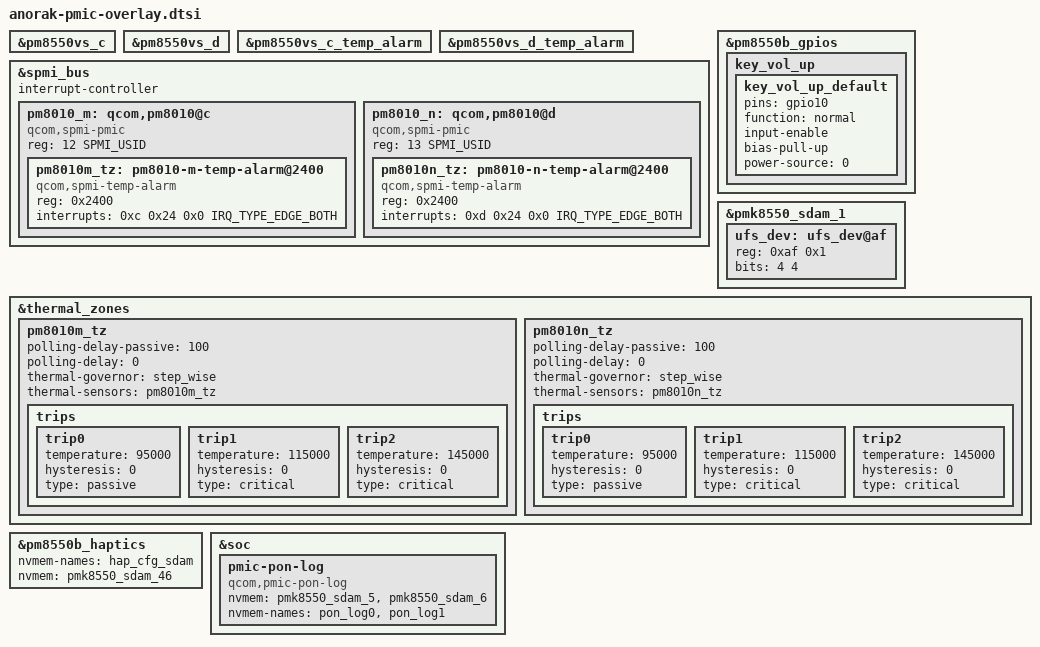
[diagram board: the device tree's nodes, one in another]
#include <dt-bindings/gpio/gpio.h>
#include <dt-bindings/pinctrl/qcom,pmic-gpio.h>

#include "pmxr2230.dtsi"
#include "pm8550b.dtsi"
#include "pm8550ve.dtsi"
#include "pm8550vs.dtsi"
#include "pmk8550.dtsi"

&pm8550vs_c {
	status = "ok";
};

&pm8550vs_d {
	status = "ok";
};

&pm8550vs_c_temp_alarm {
	status = "ok";
};

&pm8550vs_d_temp_alarm {
	status = "ok";
};

&spmi_bus {
	#address-cells = <2>;
	#size-cells = <0>;
	interrupt-controller;
	#interrupt-cells = <4>;

	pm8010_m: qcom,pm8010@c {
		compatible = "qcom,spmi-pmic";
		reg = <12 SPMI_USID>;
		#address-cells = <1>;
		#size-cells = <0>;

		pm8010m_tz: pm8010-m-temp-alarm@2400 {
			compatible = "qcom,spmi-temp-alarm";
			reg = <0x2400>;
			interrupts = <0xc 0x24 0x0 IRQ_TYPE_EDGE_BOTH>;
			#thermal-sensor-cells = <0>;
		};
	};

	pm8010_n: qcom,pm8010@d {
		compatible = "qcom,spmi-pmic";
		reg = <13 SPMI_USID>;
		#address-cells = <1>;
		#size-cells = <0>;

		pm8010n_tz: pm8010-n-temp-alarm@2400 {
			compatible = "qcom,spmi-temp-alarm";
			reg = <0x2400>;
			interrupts = <0xd 0x24 0x0 IRQ_TYPE_EDGE_BOTH>;
			#thermal-sensor-cells = <0>;
		};
	};
};

&pm8550b_gpios {
	key_vol_up {
		key_vol_up_default: key_vol_up_default {
			pins = "gpio10";
			function = "normal";
			input-enable;
			bias-pull-up;
			power-source = <0>;
		};
	};
};

&pmk8550_sdam_1 {
	ufs_dev: ufs_dev@af {
		reg = <0xaf 0x1>;
		bits = <4 4>;
	};
};

&thermal_zones {
	pm8010m_tz {
		polling-delay-passive = <100>;
		polling-delay = <0>;
		thermal-governor = "step_wise";
		thermal-sensors = <&pm8010m_tz>;

		trips {
			trip0 {
				temperature = <95000>;
				hysteresis = <0>;
				type = "passive";
			};

			trip1 {
				temperature = <115000>;
				hysteresis = <0>;
				type = "critical";
			};

			trip2 {
				temperature = <145000>;
				hysteresis = <0>;
				type = "critical";
			};
		};
	};

	pm8010n_tz {
		polling-delay-passive = <100>;
		polling-delay = <0>;
		thermal-governor = "step_wise";
		thermal-sensors = <&pm8010n_tz>;

		trips {
			trip0 {
				temperature = <95000>;
				hysteresis = <0>;
				type = "passive";
			};

			trip1 {
				temperature = <115000>;
				hysteresis = <0>;
				type = "critical";
			};

			trip2 {
				temperature = <145000>;
				hysteresis = <0>;
				type = "critical";
			};
		};
	};
};

&pm8550b_haptics {
	nvmem-names = "hap_cfg_sdam";
	nvmem = <&pmk8550_sdam_46>;
};

&soc {
	pmic-pon-log {
		compatible = "qcom,pmic-pon-log";
		nvmem = <&pmk8550_sdam_5>, <&pmk8550_sdam_6>;
		nvmem-names = "pon_log0", "pon_log1";
	};
};
